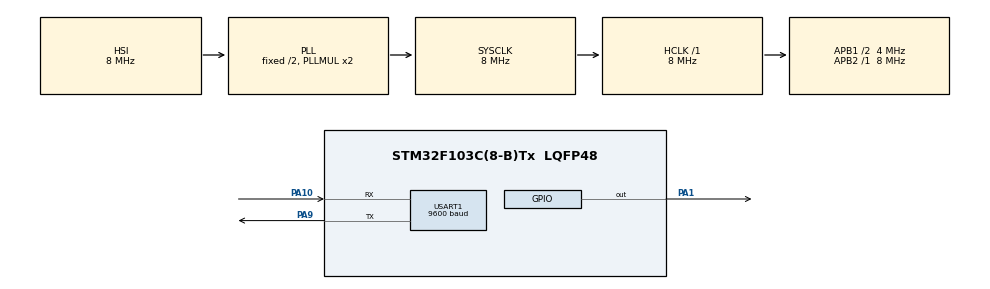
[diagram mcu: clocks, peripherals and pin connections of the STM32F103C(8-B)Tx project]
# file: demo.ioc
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Mcu.Family=STM32F1
Mcu.Name=STM32F103C(8-B)Tx
Mcu.Package=LQFP48
NVIC.PriorityGroup=NVIC_PRIORITYGROUP_4
PA1.Signal=GPIO_Output
PA10.Mode=Asynchronous
PA10.Signal=USART1_RX
PA13.Mode=JTAG_5_pins
PA13.Signal=SYS_JTMS-SWDIO
PA14.Mode=JTAG_5_pins
PA14.Signal=SYS_JTCK-SWCLK
PA15.Mode=JTAG_5_pins
PA15.Signal=SYS_JTDI
PA9.Mode=Asynchronous
PA9.Signal=USART1_TX
PB3.Mode=JTAG_5_pins
PB3.Signal=SYS_JTDO-TRACESWO
PB4.Mode=JTAG_5_pins
PB4.Signal=SYS_NJTRST
ProjectManager.HeapSize=0x200
ProjectManager.StackSize=0x400
ProjectManager.TargetToolchain=MDK-ARM V5.32
RCC.AHBFreq_Value=8000000
RCC.APB1CLKDivider=RCC_HCLK_DIV2
RCC.APB1Freq_Value=4000000
RCC.APB1TimFreq_Value=8000000
RCC.APB2Freq_Value=8000000
RCC.APB2TimFreq_Value=8000000
RCC.HCLKFreq_Value=8000000
RCC.SYSCLKFreq_VALUE=8000000
RCC.SYSCLKSource=RCC_SYSCLKSOURCE_PLLCLK
RCC.USBFreq_Value=8000000
USART1.BaudRate=9600
USART1.VirtualMode=VM_ASYNC
board=custom

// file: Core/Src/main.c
/* USER CODE BEGIN Header */
/**
  ******************************************************************************
  * @file           : main.c
  * @brief          : Main program body
  ******************************************************************************
  * @attention
  *
  * Copyright (c) 2023 STMicroelectronics.
  * All rights reserved.
  *
  * This software is licensed under terms that can be found in the LICENSE file
  * in the root directory of this software component.
  * If no LICENSE file comes with this software, it is provided AS-IS.
  *
  ******************************************************************************
  */
/* USER CODE END Header */
#include "main.h"
#include "usart.h"
#include "gpio.h"

/* USER CODE BEGIN Includes */
#include "delay.h"
/* USER CODE END Includes */

void SystemClock_Config(void);

int main(void)
{

  /* MCU Configuration--------------------------------------------------------*/

  /* Reset of all peripherals, Initializes the Flash interface and the Systick. */
  HAL_Init();

  /* Configure the system clock */
  SystemClock_Config();

  /* Initialize all configured peripherals */
  MX_GPIO_Init();
  MX_USART1_UART_Init();

  /* Infinite loop */
  while (1)
  {

    /* USER CODE BEGIN 3 */
		HAL_GPIO_WritePin(GPIOA, GPIO_PIN_1, GPIO_PIN_SET);
//		HAL_Delay(1);
		Delay_ms(1000);
		HAL_GPIO_WritePin(GPIOA, GPIO_PIN_1, GPIO_PIN_RESET);
//		HAL_Delay(1);
		uint8_t TEMP_BUF[] = {0x01, 0x02, 0x03, 0x04};
		HAL_UART_Transmit(&huart1, (uint8_t*)TEMP_BUF, 4, 0xffff);
		Delay_ms(1000);
  }
  /* USER CODE END 3 */
}

void SystemClock_Config(void)
{
  RCC_OscInitTypeDef RCC_OscInitStruct = {0};
  RCC_ClkInitTypeDef RCC_ClkInitStruct = {0};

  /** Initializes the RCC Oscillators according to the specified parameters
  * in the RCC_OscInitTypeDef structure.
  */
  RCC_OscInitStruct.OscillatorType = RCC_OSCILLATORTYPE_HSI;
  RCC_OscInitStruct.HSIState = RCC_HSI_ON;
  RCC_OscInitStruct.HSICalibrationValue = RCC_HSICALIBRATION_DEFAULT;
  RCC_OscInitStruct.PLL.PLLState = RCC_PLL_ON;
  RCC_OscInitStruct.PLL.PLLSource = RCC_PLLSOURCE_HSI_DIV2;
  RCC_OscInitStruct.PLL.PLLMUL = RCC_PLL_MUL2;
  if (HAL_RCC_OscConfig(&RCC_OscInitStruct) != HAL_OK)
  {
    Error_Handler();
  }

  /** Initializes the CPU, AHB and APB buses clocks
  */
  RCC_ClkInitStruct.ClockType = RCC_CLOCKTYPE_HCLK|RCC_CLOCKTYPE_SYSCLK
                              |RCC_CLOCKTYPE_PCLK1|RCC_CLOCKTYPE_PCLK2;
  RCC_ClkInitStruct.SYSCLKSource = RCC_SYSCLKSOURCE_PLLCLK;
  RCC_ClkInitStruct.AHBCLKDivider = RCC_SYSCLK_DIV1;
  RCC_ClkInitStruct.APB1CLKDivider = RCC_HCLK_DIV2;
  RCC_ClkInitStruct.APB2CLKDivider = RCC_HCLK_DIV1;

  if (HAL_RCC_ClockConfig(&RCC_ClkInitStruct, FLASH_LATENCY_0) != HAL_OK)
  {
    Error_Handler();
  }
}

void Error_Handler(void)
{
  __disable_irq();
  while (1)
  {
  }
}
